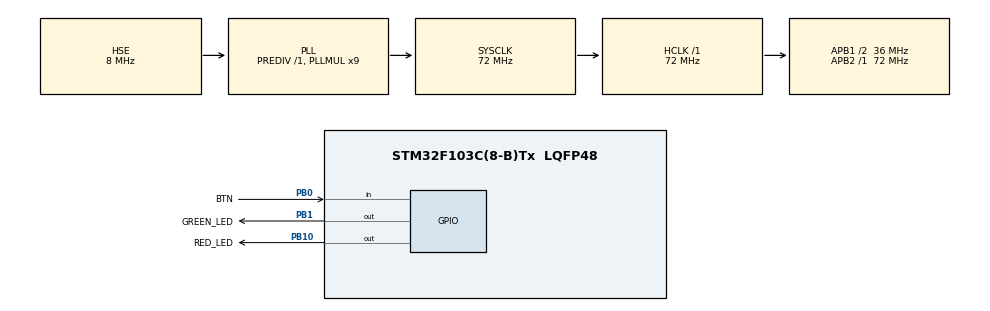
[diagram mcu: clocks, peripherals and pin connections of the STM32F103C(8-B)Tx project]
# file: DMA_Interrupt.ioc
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Dma.MEMTOMEM.0.Direction=DMA_MEMORY_TO_MEMORY
Dma.MEMTOMEM.0.Instance=DMA1_Channel1
Dma.MEMTOMEM.0.MemDataAlignment=DMA_MDATAALIGN_WORD
Dma.MEMTOMEM.0.MemInc=DMA_MINC_ENABLE
Dma.MEMTOMEM.0.Mode=DMA_NORMAL
Dma.MEMTOMEM.0.PeriphDataAlignment=DMA_PDATAALIGN_WORD
Dma.MEMTOMEM.0.PeriphInc=DMA_PINC_ENABLE
Dma.MEMTOMEM.0.Priority=DMA_PRIORITY_LOW
Dma.Request0=MEMTOMEM
Mcu.Family=STM32F1
Mcu.Name=STM32F103C(8-B)Tx
Mcu.Package=LQFP48
NVIC.DMA1_Channel1_IRQn=true\:0\:0\:false\:false\:true\:true\:true\:true
NVIC.PriorityGroup=NVIC_PRIORITYGROUP_4
PA13.Mode=Serial_Wire
PA13.Signal=SYS_JTMS-SWDIO
PA14.Mode=Serial_Wire
PA14.Signal=SYS_JTCK-SWCLK
PB0.GPIO_Label=BTN
PB0.GPIO_PuPd=GPIO_PULLUP
PB0.Signal=GPIO_Input
PB1.GPIO_Label=GREEN_LED
PB1.Signal=GPIO_Output
PB10.GPIO_Label=RED_LED
PB10.Signal=GPIO_Output
PD0-OSC_IN.Mode=HSE-External-Oscillator
PD0-OSC_IN.Signal=RCC_OSC_IN
PD1-OSC_OUT.Mode=HSE-External-Oscillator
PD1-OSC_OUT.Signal=RCC_OSC_OUT
ProjectManager.HeapSize=0x200
ProjectManager.StackSize=0x400
ProjectManager.TargetToolchain=MDK-ARM V5.32
RCC.AHBFreq_Value=72000000
RCC.APB1CLKDivider=RCC_HCLK_DIV2
RCC.APB1Freq_Value=36000000
RCC.APB1TimFreq_Value=72000000
RCC.APB2Freq_Value=72000000
RCC.APB2TimFreq_Value=72000000
RCC.HCLKFreq_Value=72000000
RCC.PLLMUL=RCC_PLL_MUL9
RCC.PLLSourceVirtual=RCC_PLLSOURCE_HSE
RCC.SYSCLKFreq_VALUE=72000000
RCC.SYSCLKSource=RCC_SYSCLKSOURCE_PLLCLK
RCC.USBFreq_Value=72000000
board=custom

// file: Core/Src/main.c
/* USER CODE BEGIN Header */
/**
  ******************************************************************************
  * @file           : main.c
  * @brief          : Main program body
  ******************************************************************************
  * @attention
  *
  * Copyright (c) 2025 STMicroelectronics.
  * All rights reserved.
  *
  * This software is licensed under terms that can be found in the LICENSE file
  * in the root directory of this software component.
  * If no LICENSE file comes with this software, it is provided AS-IS.
  *
  ******************************************************************************
  */
/* USER CODE END Header */
#include "main.h"

DMA_HandleTypeDef hdma_memtomem_dma1_channel1;

void SystemClock_Config(void);
static void MX_GPIO_Init(void);
static void MX_DMA_Init(void);
/* USER CODE BEGIN PFP */
uint8_t BufferCmp(uint32_t* pBuff1,uint32_t* pBuff2,uint16_t length);
static void TransferCompelete(DMA_HandleTypeDef * hdma);
/* USER CODE END PFP */

/* USER CODE BEGIN 0 */

#define BUFFER_SIZE 32

uint32_t srcBuffer[BUFFER_SIZE]={
		0xfa3274eb, 0xa36155a3, 0x256c72c8, 0x66fac0f4,
		0x860e7c18, 0x2a746e5d, 0x4483f65c, 0xb540baaf,
		0xb87e246d, 0xb116bb02, 0xf88b5e26, 0xf15ead10,
		0x90d4a147, 0xf5e0e280, 0x8e16e2c0, 0x8048065c,
		0xd6d4a75c, 0x813f75b0, 0xf978e5fd, 0x739f6c5c,
		0xa2514519, 0x40f86b18, 0x29d3f63a, 0x259a6378,
		0x31c9b8cc, 0x491c0200, 0xa8b49680, 0xeabac936,
		0x30111c1d, 0x55d3c6a4, 0xfbbccb02, 0x75a4e504
	};

	uint32_t dstBuffer[BUFFER_SIZE];

/* USER CODE END 0 */

int main(void)
{

  /* MCU Configuration--------------------------------------------------------*/

  /* Reset of all peripherals, Initializes the Flash interface and the Systick. */
  HAL_Init();

  /* Configure the system clock */
  SystemClock_Config();

  /* Initialize all configured peripherals */
  MX_GPIO_Init();
  MX_DMA_Init();
  /* USER CODE BEGIN 2 */
	/* set the transfer compelete interrupt callback */
  hdma_memtomem_dma1_channel1.XferCpltCallback = TransferCompelete;

  /* USER CODE END 2 */

  /* Infinite loop */
  /* USER CODE BEGIN WHILE */
  while (1)
  {
		while(HAL_GPIO_ReadPin(BTN_GPIO_Port,BTN_Pin));

		HAL_DMA_Start_IT(&hdma_memtomem_dma1_channel1, (uint32_t)&srcBuffer,
												(uint32_t)dstBuffer,BUFFER_SIZE);

    /* USER CODE END WHILE */

  }
}

void SystemClock_Config(void)
{
  RCC_OscInitTypeDef RCC_OscInitStruct = {0};
  RCC_ClkInitTypeDef RCC_ClkInitStruct = {0};

  /** Initializes the RCC Oscillators according to the specified parameters
  * in the RCC_OscInitTypeDef structure.
  */
  RCC_OscInitStruct.OscillatorType = RCC_OSCILLATORTYPE_HSE;
  RCC_OscInitStruct.HSEState = RCC_HSE_ON;
  RCC_OscInitStruct.HSEPredivValue = RCC_HSE_PREDIV_DIV1;
  RCC_OscInitStruct.HSIState = RCC_HSI_ON;
  RCC_OscInitStruct.PLL.PLLState = RCC_PLL_ON;
  RCC_OscInitStruct.PLL.PLLSource = RCC_PLLSOURCE_HSE;
  RCC_OscInitStruct.PLL.PLLMUL = RCC_PLL_MUL9;
  if (HAL_RCC_OscConfig(&RCC_OscInitStruct) != HAL_OK)
  {
    Error_Handler();
  }

  /** Initializes the CPU, AHB and APB buses clocks
  */
  RCC_ClkInitStruct.ClockType = RCC_CLOCKTYPE_HCLK|RCC_CLOCKTYPE_SYSCLK
                              |RCC_CLOCKTYPE_PCLK1|RCC_CLOCKTYPE_PCLK2;
  RCC_ClkInitStruct.SYSCLKSource = RCC_SYSCLKSOURCE_PLLCLK;
  RCC_ClkInitStruct.AHBCLKDivider = RCC_SYSCLK_DIV1;
  RCC_ClkInitStruct.APB1CLKDivider = RCC_HCLK_DIV2;
  RCC_ClkInitStruct.APB2CLKDivider = RCC_HCLK_DIV1;

  if (HAL_RCC_ClockConfig(&RCC_ClkInitStruct, FLASH_LATENCY_2) != HAL_OK)
  {
    Error_Handler();
  }
}

static void MX_DMA_Init(void)
{

  /* DMA controller clock enable */
  __HAL_RCC_DMA1_CLK_ENABLE();

  /* Configure DMA request hdma_memtomem_dma1_channel1 on DMA1_Channel1 */
  hdma_memtomem_dma1_channel1.Instance = DMA1_Channel1;
  hdma_memtomem_dma1_channel1.Init.Direction = DMA_MEMORY_TO_MEMORY;
  hdma_memtomem_dma1_channel1.Init.PeriphInc = DMA_PINC_ENABLE;
  hdma_memtomem_dma1_channel1.Init.MemInc = DMA_MINC_ENABLE;
  hdma_memtomem_dma1_channel1.Init.PeriphDataAlignment = DMA_PDATAALIGN_WORD;
  hdma_memtomem_dma1_channel1.Init.MemDataAlignment = DMA_MDATAALIGN_WORD;
  hdma_memtomem_dma1_channel1.Init.Mode = DMA_NORMAL;
  hdma_memtomem_dma1_channel1.Init.Priority = DMA_PRIORITY_LOW;
  if (HAL_DMA_Init(&hdma_memtomem_dma1_channel1) != HAL_OK)
  {
    Error_Handler( );
  }

  /* DMA interrupt init */
  /* DMA1_Channel1_IRQn interrupt configuration */
  HAL_NVIC_SetPriority(DMA1_Channel1_IRQn, 0, 0);
  HAL_NVIC_EnableIRQ(DMA1_Channel1_IRQn);

}

static void MX_GPIO_Init(void)
{
  GPIO_InitTypeDef GPIO_InitStruct = {0};

  /* GPIO Ports Clock Enable */
  __HAL_RCC_GPIOD_CLK_ENABLE();
  __HAL_RCC_GPIOB_CLK_ENABLE();
  __HAL_RCC_GPIOA_CLK_ENABLE();

  /*Configure GPIO pin Output Level */
  HAL_GPIO_WritePin(GPIOB, GREEN_LED_Pin|RED_LED_Pin, GPIO_PIN_RESET);

  /*Configure GPIO pin : BTN_Pin */
  GPIO_InitStruct.Pin = BTN_Pin;
  GPIO_InitStruct.Mode = GPIO_MODE_INPUT;
  GPIO_InitStruct.Pull = GPIO_PULLUP;
  HAL_GPIO_Init(BTN_GPIO_Port, &GPIO_InitStruct);

  /*Configure GPIO pins : GREEN_LED_Pin RED_LED_Pin */
  GPIO_InitStruct.Pin = GREEN_LED_Pin|RED_LED_Pin;
  GPIO_InitStruct.Mode = GPIO_MODE_OUTPUT_PP;
  GPIO_InitStruct.Pull = GPIO_NOPULL;
  GPIO_InitStruct.Speed = GPIO_SPEED_FREQ_LOW;
  HAL_GPIO_Init(GPIOB, &GPIO_InitStruct);

}

void Error_Handler(void)
{
  __disable_irq();
  while (1)
  {
  }
}
uint8_t BufferCmp(uint32_t* pBuff1,uint32_t* pBuff2,uint16_t length){
	while(length--){

		if(*pBuff1 != *pBuff2){
			return 1;
		}
		pBuff1++;
		pBuff2++;
	}
	return 0;
}

static void TransferCompelete(DMA_HandleTypeDef * hdma){

	if(BufferCmp((uint32_t*)srcBuffer , (uint32_t*)dstBuffer , BUFFER_SIZE)){
		HAL_GPIO_WritePin(RED_LED_GPIO_Port, RED_LED_Pin, GPIO_PIN_SET);
	}
	else{
		HAL_GPIO_WritePin(GREEN_LED_GPIO_Port, GREEN_LED_Pin, GPIO_PIN_SET);
	}

}
